# MCU_CTRL_MMR_MCU_CTRL_MMR_CFG0_04500000h register map
Vendor: Texas Instruments
Registers are 32-bit, read-write, reset 0x0 unless marked. A register's access mark holds for its fields unless they carry their own. Offsets are as the file gives them; [hi:lo] are bit positions; {n}, {i} and the like mark numbered series.

## MCU_CTRL_MMR_CFG0 (part 3 of 3)
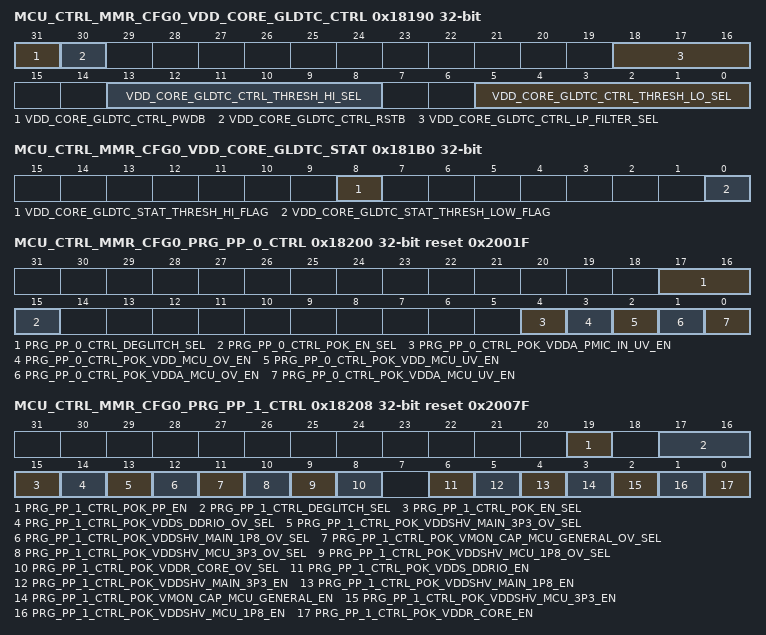
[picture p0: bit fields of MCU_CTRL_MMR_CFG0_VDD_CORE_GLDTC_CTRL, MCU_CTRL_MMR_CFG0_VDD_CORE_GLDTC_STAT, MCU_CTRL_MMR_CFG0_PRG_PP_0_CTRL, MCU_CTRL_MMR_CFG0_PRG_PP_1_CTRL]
0x18190 MCU_CTRL_MMR_CFG0_VDD_CORE_GLDTC_CTRL
  [31] VDD_CORE_GLDTC_CTRL_PWDB — Power down - active low. 0 - Deactivate all functions 1 - Activate glitch detectors Reset Source: mcu_chip1_rst_n
  [30] VDD_CORE_GLDTC_CTRL_RSTB — Reset - active low. To ensure proper operation, rstb must be not be de-asserted for at least 100 ns after power-up (pwdb de-asserted). Additionally, rstb must be toggled low at least 200 ns after any change in threshold or low-pass filter settings to prevent abnormal trigger events. 0 - Reset glitch detector flags 1 - Glitch detection flags are activated Reset Source: mcu_chip1_rst_n
  [18:16] VDD_CORE_GLDTC_CTRL_LP_FILTER_SEL — Selects the glitch detect low-pass filter bandwidthField values (others are reserved):3'b000 - 150 kHz3'b001 - 125 kHz3'b010 - 100 kHz3'b011 - 80 kHz3'b100 - 60 kHz3'b101 - 45 kHz3'b110 - 30 kHz3'b111 - 15 kHz Reset Source: mcu_chip1_rst_n
  [13:8] VDD_CORE_GLDTC_CTRL_THRESH_HI_SEL — Selects the high voltage glitch threshold as a percentage of the monitored voltageField values (others are reserved):6'b000000 - 93.5% of VDD6'b000001 - 94.0% of VDD6'b000010 - 94.5% of VDD6'b000011 - 95.0% of VDD6'b000100 - 95.5% of VDD6'b000101 - 96.0% of VDD6'b000110 - 96.5% of VDD6'b000111 - 97.0% of VDD6'b001000 - 97.5% of VDD6'b001001 - 98.0% of VDD6'b001010 - 98.5% of VDD6'b001011 - 99.0% of VDD6'b001100 - 99.5% of VDD6'b001101 - 100.0% of VDD6'b001110 - 100.5% of VDD6'b001111 - 101.0% of VDD6'b010000 - 101.5% of VDD6'b010001 - 102.0% of VDD6'b010010 - 102.5% of VDD6'b010011 - 103.0% of VDD6'b010100 - 103.5% of VDD6'b010101 - 104.0% of VDD6'b010110 - 104.5% of VDD6'b010111 - 105.0% of VDD6'b011000 - 105.5% of VDD6'b011001 - 106.0% of VDD6'b011010 - 106.5% of VDD6'b011011 - 107.0% of VDD6'b011100 - 107.5% of VDD6'b011101 - 108.0% of VDD6'b011110 - 108.5% of VDD6'b011111 - 109.0% of VDD6'b100000 - 109.5% of VDD6'b100001 - 110.0% of VDD6'b100010 - 111.0% of VDD6'b100011 - 112.0% of VDD6'b100100 - 113.0% of VDD6'b100101 - 114.0% of VDD6'b100110 - 115.0% of VDD6'b100111 - 116.0% of VDD6'b101000 - 117.0% of VDD6'b101001 - 118.0% of VDD6'b101010 - 119.0% of VDD6'b101011 - 120.0% of VDD6'b101100 - 121.0% of VDD6'b101101 - 122.0% of VDD6'b101110 - 123.0% of VDD6'b101111 - 124.0% of VDD6'b110000 - 125.0% of VDD6'b110001 - 126.0% of VDD6'b110010 - 127.0% of VDD6'b110011 - 128.0% of VDD6'b110100 - 129.0% of VDD6'b110101 - 130.0% of VDD6'b110110 - 131.0% of VDD6'b110111 - 132.0% of VDD6'b111000 - 133.0% of VDD6'b111001 - 134.0% of VDD6'b111010 - 135.0% of VDD6'b111011 - 136.0% of VDD6'b111100 - 137.0% of VDD6'b111101 - 138.0% of VDD6'b111110 - 139.0% of VDD6'b111111 - 140.0% of VDD Reset Source: mcu_chip1_rst_n
  [5:0] VDD_CORE_GLDTC_CTRL_THRESH_LO_SEL — Selects the low voltage glitch threshold as a percentage of the monitored voltageField values (others are reserved):6'b000000 - 106.5% of VDD6'b000001 - 106.0% of VDD6'b000010 - 105.5% of VDD6'b000011 - 105.0% of VDD6'b000100 - 104.5% of VDD6'b000101 - 104.0% of VDD6'b000110 - 103.5% of VDD6'b000111 - 103.0% of VDD6'b001000 - 102.5% of VDD6'b001001 - 102.0% of VDD6'b001010 - 101.5% of VDD6'b001011 - 101.0% of VDD6'b001100 - 100.5% of VDD6'b001101 - 100.0% of VDD6'b001110 - 99.5% of VDD6'b001111 - 99.0% of VDD6'b010000 - 98.5% of VDD6'b010001 - 98.0% of VDD6'b010010 - 97.5% of VDD6'b010011 - 97.0% of VDD6'b010100 - 96.5% of VDD6'b010101 - 96.0% of VDD6'b010110 - 95.5% of VDD6'b010111 - 95.0% of VDD6'b011000 - 94.5% of VDD6'b011001 - 94.0% of VDD6'b011010 - 93.5% of VDD6'b011011 - 93.0% of VDD6'b011100 - 92.5% of VDD6'b011101 - 92.0% of VDD6'b011110 - 91.5% of VDD6'b011111 - 91.0% of VDD6'b100000 - 90.5% of VDD6'b100001 - 90.0% of VDD6'b100010 - 89.0% of VDD6'b100011 - 88.0% of VDD6'b100100 - 87.0% of VDD6'b100101 - 86.0% of VDD6'b100110 - 85.0% of VDD6'b100111 - 84.0% of VDD6'b101000 - 83.0% of VDD6'b101001 - 82.0% of VDD6'b101010 - 81.0% of VDD6'b101011 - 80.0% of VDD6'b101100 - 79.0% of VDD6'b101101 - 78.0% of VDD6'b101110 - 77.0% of VDD6'b101111 - 76.0% of VDD6'b110000 - 75.0% of VDD6'b110001 - 74.0% of VDD6'b110010 - 73.0% of VDD6'b110011 - 72.0% of VDD6'b110100 - 71.0% of VDD6'b110101 - 70.0% of VDD6'b110110 - 69.0% of VDD6'b110111 - 68.0% of VDD6'b111000 - 67.0% of VDD6'b111001 - 66.0% of VDD6'b111010 - 65.0% of VDD6'b111011 - 64.0% of VDD6'b111100 - 63.0% of VDD6'b111101 - 62.0% of VDD6'b111110 - 61.0% of VDD6'b111111 - 60.0% of VDD Reset Source: mcu_chip1_rst_n
0x181B0 MCU_CTRL_MMR_CFG0_VDD_CORE_GLDTC_STAT ro
  [8] VDD_CORE_GLDTC_STAT_THRESH_HI_FLAG — High voltage flag. This flag is cleared by clearing the VDD_CORE_GLDTC_CTRL_rstb bit. 0 - No high voltage detected 1 - Voltage above the high voltage threshold was detected. Reset Source: mcu_chip1_rst_n
  [0] VDD_CORE_GLDTC_STAT_THRESH_LOW_FLAG — Low voltage flag. This flag is cleared by clearing the VDD_CORE_GLDTC_CTRL_rstb bit. 0 - No low voltage detected 1 - Voltage below the low voltage threshold was detected. Reset Source: mcu_chip1_rst_n
0x18200 MCU_CTRL_MMR_CFG0_PRG_PP_0_CTRL reset 0x2001F
  [17:16] PRG_PP_0_CTRL_DEGLITCH_SEL — Deglitch period for PRG_PP0 POKs:2'b00 - 5 us2'b01 -10 us2'b10 - 15 us2'b11 - 20us Reset Source: mod_por_rst_n
  [15] PRG_PP_0_CTRL_POK_EN_SEL — Select POK activate source0 - POK activates come from hardware tie-offs1 - POK activates come from PRG_PP0_CTRL register Reset Source: mod_por_rst_n
  [4] PRG_PP_0_CTRL_POK_VDDA_PMIC_IN_UV_EN — Activate VDDA_PMIC_IN undervoltage POK detection0 - POK detection deactivated1 - POK detection activated Reset Source: mod_por_rst_n
  [3] PRG_PP_0_CTRL_POK_VDD_MCU_OV_EN — Activate VDD_MCU overvoltage POK detection0 - POK detection deactivated1 - POK detection activated Reset Source: mod_por_rst_n
  [2] PRG_PP_0_CTRL_POK_VDD_MCU_UV_EN — Activate VDD_MCU undervoltage POK detection0 - POK detection deactivated1 - POK detection activated Reset Source: mod_por_rst_n
  [1] PRG_PP_0_CTRL_POK_VDDA_MCU_OV_EN — Activate 1.8V VDDA_MCU overvoltage POK detection0 - POK detection deactivated1 - POK detection activated Reset Source: mod_por_rst_n
  [0] PRG_PP_0_CTRL_POK_VDDA_MCU_UV_EN — Activate 1.8V VDDA_MCU undervoltage POK detection0 - POK detection deactivated1 - POK detection activated Reset Source: mod_por_rst_n
0x18208 MCU_CTRL_MMR_CFG0_PRG_PP_1_CTRL reset 0x2007F
  [19] PRG_PP_1_CTRL_POK_PP_EN — POK ping-pong activate. When set, activatesautomatic switching between undervoltage andovervoltage detection on PRG_PP1 (POK_VDDR_CORE, POK_VDDSHV_MCU_1P8, POK_VDDSHV_MCU_3P3, POK_VMON_CAP_MCU_GENERAL, POK_VDDSHV_MAIN_1P8, POK_VDDSHV_MAIN_3P3, and POK_VDDS_DDRIO) POKs. This bit has no effect if the POK's ov_sel bit = 1.0 - No pingpong operation. UV/OV operationselected by each POK ov_sel bit1 - Pingpong operation activated . Reset Source: mod_por_rst_n
  [17:16] PRG_PP_1_CTRL_DEGLITCH_SEL — Deglitch period for PRG_PP1 POKs:2'b00 - 5 us2'b01 -10 us2'b10 - 15 us2'b11 - 20us Reset Source: mod_por_rst_n
  [15] PRG_PP_1_CTRL_POK_EN_SEL — Select POK activate source0 - POK activates come from hardware tie-offs1 - POK activates come from PRG_PP1_CTRL register Reset Source: mod_por_rst_n
  [14] PRG_PP_1_CTRL_POK_VDDS_DDRIO_OV_SEL — POK_VDDS_DDRIO mode: 0 = Undervoltage (pok_pp_en = 0) Ping-Pong (pok_pp_en = 1) 1 = Overvoltage (pok_pp_en = x) Reset Source: mod_por_rst_n
  [13] PRG_PP_1_CTRL_POK_VDDSHV_MAIN_3P3_OV_SEL — POK_VDDSHV_MAIN_3P3 mode: 0 = Undervoltage (pok_pp_en = 0) Ping-Pong (pok_pp_en = 1) 1 = Overvoltage (pok_pp_en = x) Reset Source: mod_por_rst_n
  [12] PRG_PP_1_CTRL_POK_VDDSHV_MAIN_1P8_OV_SEL — POK_VDDSHV_MAIN_1P8 mode: 0 = Undervoltage (pok_pp_en = 0) Ping-Pong (pok_pp_en = 1) 1 = Overvoltage (pok_pp_en = x) Reset Source: mod_por_rst_n
  [11] PRG_PP_1_CTRL_POK_VMON_CAP_MCU_GENERAL_OV_SEL — POK_VMON_CAP_MCU_GENERAL mode: 0 = Undervoltage (pok_pp_en = 0) Ping-Pong (pok_pp_en = 1) 1 = Overvoltage (pok_pp_en = x) Reset Source: mod_por_rst_n
  [10] PRG_PP_1_CTRL_POK_VDDSHV_MCU_3P3_OV_SEL — POK_VDDSHV_MCU_3P3 mode: 0 = Undervoltage (pok_pp_en = 0) Ping-Pong (pok_pp_en = 1) 1 = Overvoltage (pok_pp_en = x) Reset Source: mod_por_rst_n
  [9] PRG_PP_1_CTRL_POK_VDDSHV_MCU_1P8_OV_SEL — POK_VDDSHV_MCU_1P8 mode: 0 = Undervoltage (pok_pp_en = 0) Ping-Pong (pok_pp_en = 1) 1 = Overvoltage (pok_pp_en = x) Reset Source: mod_por_rst_n
  [8] PRG_PP_1_CTRL_POK_VDDR_CORE_OV_SEL — POK_VDDR_CORE Mode: 0 = Undervoltage (pok_pp_en = 0) Ping-Pong (pok_pp_en = 1) 1 = Overvoltage (pok_pp_en = x) Reset Source: mod_por_rst_n
  [6] PRG_PP_1_CTRL_POK_VDDS_DDRIO_EN — Activate POK_VDDS_DDRIO (if pok_en_sel = 1): 0 = POK Detection Deactivated 1 = POK Detection Activated Reset Source: mod_por_rst_n
  [5] PRG_PP_1_CTRL_POK_VDDSHV_MAIN_3P3_EN — Activate POK_VDDSHV_MAIN_3P3 (if pok_en_sel = 1): 0 = POK Detection Deactivated 1 = POK Detection Activated Reset Source: mod_por_rst_n
  [4] PRG_PP_1_CTRL_POK_VDDSHV_MAIN_1P8_EN — Activate POK_VDDSHV_MAIN_1P8 (if pok_en_sel = 1): 0 = POK Detection Deactivated 1 = POK Detection Activated Reset Source: mod_por_rst_n
  [3] PRG_PP_1_CTRL_POK_VMON_CAP_MCU_GENERAL_EN — Activate POK_VMON_CAP_MCU_GENERAL (if pok_en_sel = 1): 0 = POK Detection Deactivated 1 = POK Detection Activated Reset Source: mod_por_rst_n
  [2] PRG_PP_1_CTRL_POK_VDDSHV_MCU_3P3_EN — Activate POK_VDDSHV_MCU_3P3 (if pok_en_sel = 1): 0 = POK Detection Deactivated 1 = POK Detection Activated Reset Source: mod_por_rst_n
  [1] PRG_PP_1_CTRL_POK_VDDSHV_MCU_1P8_EN — Activate POK_VDDSHV_MCU_1P8 (if pok_en_sel = 1): 0 = POK Detection Deactivated 1 = POK Detection Activated Reset Source: mod_por_rst_n
  [0] PRG_PP_1_CTRL_POK_VDDR_CORE_EN — Activate POK_VDDR_CORE (if pok_en_sel = 1): 0 = POK Detection Deactivated 1 = POK Detection Activated Reset Source: mod_por_rst_n
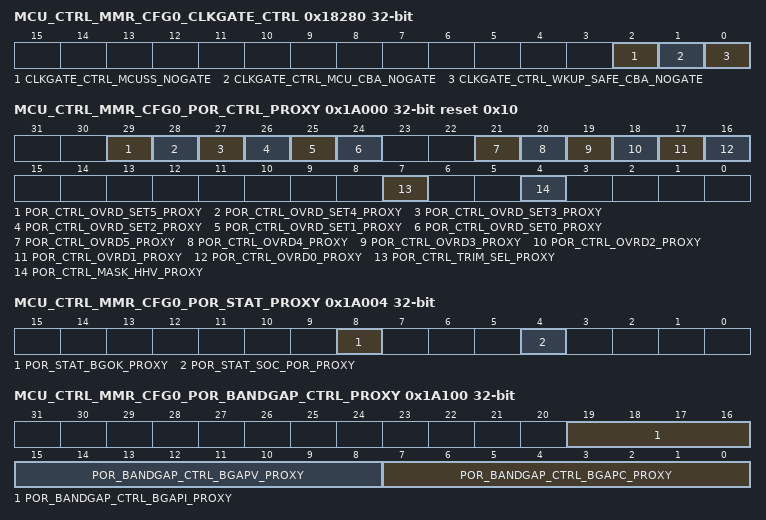
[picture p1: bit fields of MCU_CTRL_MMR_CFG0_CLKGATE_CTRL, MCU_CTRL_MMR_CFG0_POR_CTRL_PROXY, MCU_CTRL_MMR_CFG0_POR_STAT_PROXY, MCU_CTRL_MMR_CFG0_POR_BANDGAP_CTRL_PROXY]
0x18280 MCU_CTRL_MMR_CFG0_CLKGATE_CTRL
  [2] CLKGATE_CTRL_MCUSS_NOGATE — MCU Subsystem clock gate deactivate. 0 - Clocks are gated on idle for power savings 1 - Clocks are not gated on idle, power saving deactivated Reset Source: mod_por_rst_n
  [1] CLKGATE_CTRL_MCU_CBA_NOGATE — MCU domain Data bus (mcu_cbass) clock gate deactivate. 0 - Clocks are gated on idle for power savings 1 - Clocks are not gated on idle, power saving deactivated Reset Source: mod_por_rst_n
  [0] CLKGATE_CTRL_WKUP_SAFE_CBA_NOGATE — WKUP domain Infrastructure bus (wkup_safe_cbass) clock gate deactivate. 0 - Clocks are gated on idle for power savings 1 - Clocks are not gated on idle, power saving deactivated Reset Source: mod_por_rst_n
0x19008 MCU_CTRL_MMR_CFG0_LOCK6_KICK0
  [31:0] LOCK6_KICK0 — - KICK0 component Reset Source: mod_g_rst_n
0x1900C MCU_CTRL_MMR_CFG0_LOCK6_KICK1
  [31:0] LOCK6_KICK1 — - KICK1 component Reset Source: mod_g_rst_n
{0x19100+4i} MCU_CTRL_MMR_CFG0_CLAIMREG_P6_R{i}_READONLY ro (i=0..5)
  [31:0] CLAIMREG_P6_R{i}_READONLY — Claim bits for Partition 6 Reset Source: mod_g_rst_n
0x1A000 MCU_CTRL_MMR_CFG0_POR_CTRL_PROXY reset 0x10
  [29] POR_CTRL_OVRD_SET5_PROXY — Reserved override set Reset Source: mod_por_rst_n
  [28] POR_CTRL_OVRD_SET4_PROXY — POKLVB override set Reset Source: mod_por_rst_n
  [27] POR_CTRL_OVRD_SET3_PROXY — POKLVA override set Reset Source: mod_por_rst_n
  [26] POR_CTRL_OVRD_SET2_PROXY — POKHV override set Reset Source: mod_por_rst_n
  [25] POR_CTRL_OVRD_SET1_PROXY — BGOK override set Reset Source: mod_por_rst_n
  [24] POR_CTRL_OVRD_SET0_PROXY — PORHV override set Reset Source: mod_por_rst_n
  [21] POR_CTRL_OVRD5_PROXY — Reserved override activate Reset Source: mod_por_rst_n
  [20] POR_CTRL_OVRD4_PROXY — POKLVB override activate Reset Source: mod_por_rst_n
  [19] POR_CTRL_OVRD3_PROXY — POKLVA override activate Reset Source: mod_por_rst_n
  [18] POR_CTRL_OVRD2_PROXY — POKHV override activate Reset Source: mod_por_rst_n
  [17] POR_CTRL_OVRD1_PROXY — BGOK override activate Reset Source: mod_por_rst_n
  [16] POR_CTRL_OVRD0_PROXY — PORHV override activate Reset Source: mod_por_rst_n
  [7] POR_CTRL_TRIM_SEL_PROXY — POR Trim Select 0 - Trim selections for Bandgap and POKs come from HHV defaults 1 - Trim selections for Bandgap and POKs come from POR_BANDGAP_CTRL and POR_POKxxx_CTRL registers Reset Source: mod_por_rst_n
  [4] POR_CTRL_MASK_HHV_PROXY — Mask HHV/SOC_PORz outputs when applying new trim values Reset Source: mod_por_rst_n
0x1A004 MCU_CTRL_MMR_CFG0_POR_STAT_PROXY ro
  [8] POR_STAT_BGOK_PROXY — Bandgap OK status Reset Source: mod_por_rst_n
  [4] POR_STAT_SOC_POR_PROXY — POR module status 0 - Module is in functional mode 1 - Module is in reset mode Reset Source: mod_por_rst_n
0x1A100 MCU_CTRL_MMR_CFG0_POR_BANDGAP_CTRL_PROXY
  [19:16] POR_BANDGAP_CTRL_BGAPI_PROXY — Bandgap output current trim bits Reset Source: mod_por_rst_n
  [15:8] POR_BANDGAP_CTRL_BGAPV_PROXY — Bandgap output voltage magnitude trim bits Reset Source: mod_por_rst_n
  [7:0] POR_BANDGAP_CTRL_BGAPC_PROXY — Bandgap slope trim bits. Bit7 is used to calculate the offset Reset Source: mod_por_rst_n
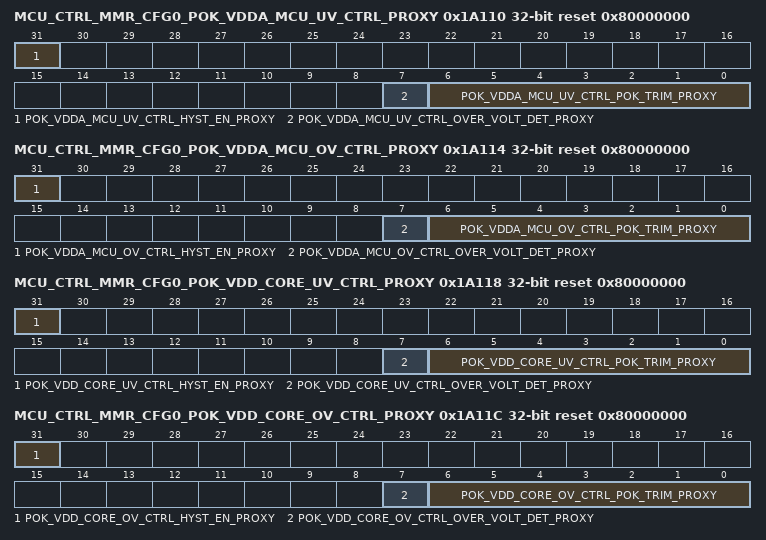
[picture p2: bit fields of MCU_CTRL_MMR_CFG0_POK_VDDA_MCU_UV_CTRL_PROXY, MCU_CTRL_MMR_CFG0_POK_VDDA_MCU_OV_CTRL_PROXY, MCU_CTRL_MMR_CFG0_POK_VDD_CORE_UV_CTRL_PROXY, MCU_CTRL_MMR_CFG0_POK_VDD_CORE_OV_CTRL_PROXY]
0x1A110 MCU_CTRL_MMR_CFG0_POK_VDDA_MCU_UV_CTRL_PROXY reset 0x80000000
  [31] POK_VDDA_MCU_UV_CTRL_HYST_EN_PROXY — Activate POK hysteresis Reset Source: mod_por_rst_n
  [7] POK_VDDA_MCU_UV_CTRL_OVER_VOLT_DET_PROXY — Over / under voltage detection mode 0 - Under voltage detection 1 - Over voltage detection Reset Source: mod_por_rst_n
  [6:0] POK_VDDA_MCU_UV_CTRL_POK_TRIM_PROXY — POK Trim Bits Reset Source: mod_por_rst_n
0x1A114 MCU_CTRL_MMR_CFG0_POK_VDDA_MCU_OV_CTRL_PROXY reset 0x80000000
  [31] POK_VDDA_MCU_OV_CTRL_HYST_EN_PROXY — Activate POK hysteresis Reset Source: mod_por_rst_n
  [7] POK_VDDA_MCU_OV_CTRL_OVER_VOLT_DET_PROXY — Over / under voltage detection mode 0 - Under voltage detection 1 - Over voltage detection Reset Source: mod_por_rst_n
  [6:0] POK_VDDA_MCU_OV_CTRL_POK_TRIM_PROXY — POK Trim Bits Reset Source: mod_por_rst_n
0x1A118 MCU_CTRL_MMR_CFG0_POK_VDD_CORE_UV_CTRL_PROXY reset 0x80000000
  [31] POK_VDD_CORE_UV_CTRL_HYST_EN_PROXY — Activate POK hysteresis Reset Source: mod_por_rst_n
  [7] POK_VDD_CORE_UV_CTRL_OVER_VOLT_DET_PROXY — Over / under voltage detection mode 0 - Under voltage detection 1 - Over voltage detection Reset Source: mod_por_rst_n
  [6:0] POK_VDD_CORE_UV_CTRL_POK_TRIM_PROXY — POK Trim Bits Reset Source: mod_por_rst_n
0x1A11C MCU_CTRL_MMR_CFG0_POK_VDD_CORE_OV_CTRL_PROXY reset 0x80000000
  [31] POK_VDD_CORE_OV_CTRL_HYST_EN_PROXY — Activate POK hysteresis Reset Source: mod_por_rst_n
  [7] POK_VDD_CORE_OV_CTRL_OVER_VOLT_DET_PROXY — Over / under voltage detection mode 0 - Under voltage detection 1 - Over voltage detection Reset Source: mod_por_rst_n
  [6:0] POK_VDD_CORE_OV_CTRL_POK_TRIM_PROXY — POK Trim Bits Reset Source: mod_por_rst_n
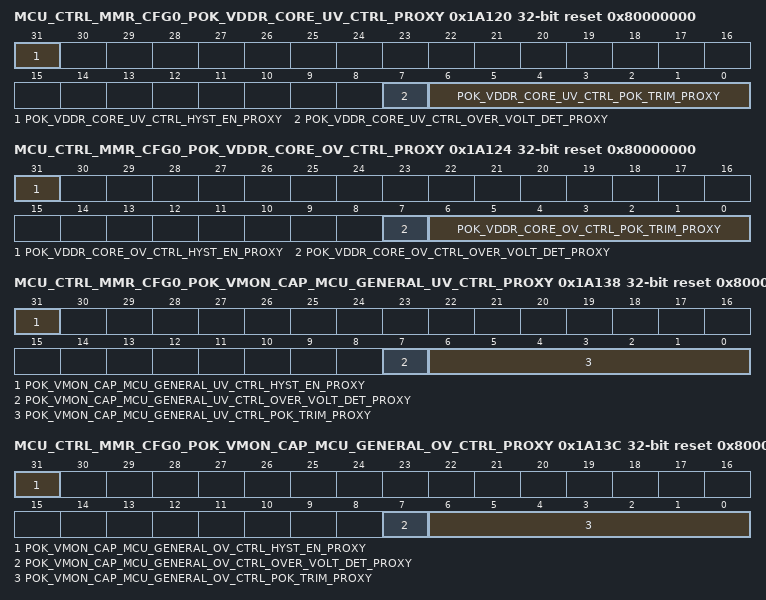
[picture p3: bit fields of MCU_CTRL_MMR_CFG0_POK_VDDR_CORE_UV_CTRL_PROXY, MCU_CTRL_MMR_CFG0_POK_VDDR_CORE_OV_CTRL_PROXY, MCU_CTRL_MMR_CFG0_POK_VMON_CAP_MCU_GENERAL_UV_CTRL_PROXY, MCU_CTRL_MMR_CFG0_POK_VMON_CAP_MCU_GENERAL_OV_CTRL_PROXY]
0x1A120 MCU_CTRL_MMR_CFG0_POK_VDDR_CORE_UV_CTRL_PROXY reset 0x80000000
  [31] POK_VDDR_CORE_UV_CTRL_HYST_EN_PROXY — Activate POK hysteresis Reset Source: mod_por_rst_n
  [7] POK_VDDR_CORE_UV_CTRL_OVER_VOLT_DET_PROXY — Over / under voltage detection mode 0 - Under voltage detection 1 - Over voltage detection Reset Source: mod_por_rst_n
  [6:0] POK_VDDR_CORE_UV_CTRL_POK_TRIM_PROXY — POK Trim Bits Reset Source: mod_por_rst_n
0x1A124 MCU_CTRL_MMR_CFG0_POK_VDDR_CORE_OV_CTRL_PROXY reset 0x80000000
  [31] POK_VDDR_CORE_OV_CTRL_HYST_EN_PROXY — Activate POK hysteresis Reset Source: mod_por_rst_n
  [7] POK_VDDR_CORE_OV_CTRL_OVER_VOLT_DET_PROXY — Over / under voltage detection mode 0 - Under voltage detection 1 - Over voltage detection Reset Source: mod_por_rst_n
  [6:0] POK_VDDR_CORE_OV_CTRL_POK_TRIM_PROXY — POK Trim Bits Reset Source: mod_por_rst_n
0x1A138 MCU_CTRL_MMR_CFG0_POK_VMON_CAP_MCU_GENERAL_UV_CTRL_PROXY reset 0x80000000
  [31] POK_VMON_CAP_MCU_GENERAL_UV_CTRL_HYST_EN_PROXY — Activate POK hysteresis Reset Source: mod_por_rst_n
  [7] POK_VMON_CAP_MCU_GENERAL_UV_CTRL_OVER_VOLT_DET_PROXY — Over / under voltage detection mode 0 - Under voltage detection 1 - Over voltage detection Reset Source: mod_por_rst_n
  [6:0] POK_VMON_CAP_MCU_GENERAL_UV_CTRL_POK_TRIM_PROXY — POK Trim Bits Reset Source: mod_por_rst_n
0x1A13C MCU_CTRL_MMR_CFG0_POK_VMON_CAP_MCU_GENERAL_OV_CTRL_PROXY reset 0x80000000
  [31] POK_VMON_CAP_MCU_GENERAL_OV_CTRL_HYST_EN_PROXY — Activate POK hysteresis Reset Source: mod_por_rst_n
  [7] POK_VMON_CAP_MCU_GENERAL_OV_CTRL_OVER_VOLT_DET_PROXY — Over / under voltage detection mode 0 - Under voltage detection 1 - Over voltage detection Reset Source: mod_por_rst_n
  [6:0] POK_VMON_CAP_MCU_GENERAL_OV_CTRL_POK_TRIM_PROXY — POK Trim Bits Reset Source: mod_por_rst_n
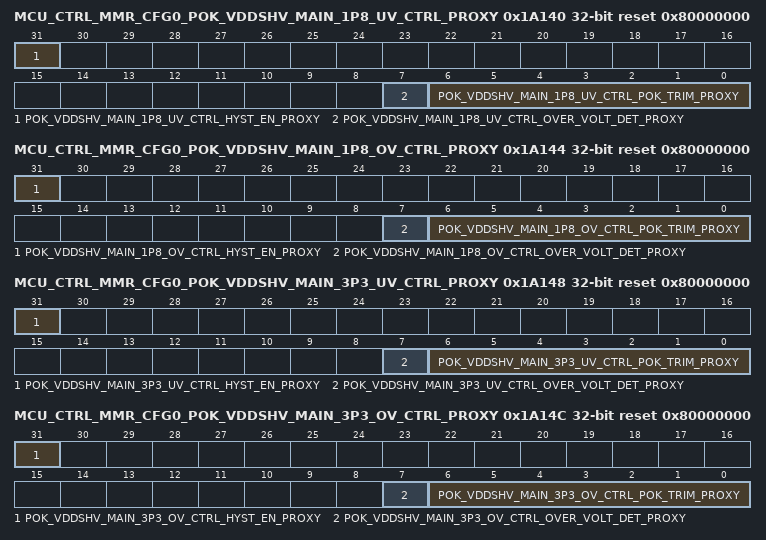
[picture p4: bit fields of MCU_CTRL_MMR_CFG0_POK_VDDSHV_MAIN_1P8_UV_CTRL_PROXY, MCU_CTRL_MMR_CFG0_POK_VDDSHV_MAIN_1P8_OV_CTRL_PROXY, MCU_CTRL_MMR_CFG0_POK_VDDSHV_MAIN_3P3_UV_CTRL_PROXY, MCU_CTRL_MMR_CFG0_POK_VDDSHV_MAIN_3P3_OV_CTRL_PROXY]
0x1A140 MCU_CTRL_MMR_CFG0_POK_VDDSHV_MAIN_1P8_UV_CTRL_PROXY reset 0x80000000
  [31] POK_VDDSHV_MAIN_1P8_UV_CTRL_HYST_EN_PROXY — Activate POK hysteresis Reset Source: mod_por_rst_n
  [7] POK_VDDSHV_MAIN_1P8_UV_CTRL_OVER_VOLT_DET_PROXY — Over / under voltage detection mode 0 - Under voltage detection 1 - Over voltage detection Reset Source: mod_por_rst_n
  [6:0] POK_VDDSHV_MAIN_1P8_UV_CTRL_POK_TRIM_PROXY — POK Trim Bits Reset Source: mod_por_rst_n
0x1A144 MCU_CTRL_MMR_CFG0_POK_VDDSHV_MAIN_1P8_OV_CTRL_PROXY reset 0x80000000
  [31] POK_VDDSHV_MAIN_1P8_OV_CTRL_HYST_EN_PROXY — Activate POK hysteresis Reset Source: mod_por_rst_n
  [7] POK_VDDSHV_MAIN_1P8_OV_CTRL_OVER_VOLT_DET_PROXY — Over / under voltage detection mode 0 - Under voltage detection 1 - Over voltage detection Reset Source: mod_por_rst_n
  [6:0] POK_VDDSHV_MAIN_1P8_OV_CTRL_POK_TRIM_PROXY — POK Trim Bits Reset Source: mod_por_rst_n
0x1A148 MCU_CTRL_MMR_CFG0_POK_VDDSHV_MAIN_3P3_UV_CTRL_PROXY reset 0x80000000
  [31] POK_VDDSHV_MAIN_3P3_UV_CTRL_HYST_EN_PROXY — Activate POK hysteresis Reset Source: mod_por_rst_n
  [7] POK_VDDSHV_MAIN_3P3_UV_CTRL_OVER_VOLT_DET_PROXY — Over / under voltage detection mode 0 - Under voltage detection 1 - Over voltage detection Reset Source: mod_por_rst_n
  [6:0] POK_VDDSHV_MAIN_3P3_UV_CTRL_POK_TRIM_PROXY — POK Trim Bits Reset Source: mod_por_rst_n
0x1A14C MCU_CTRL_MMR_CFG0_POK_VDDSHV_MAIN_3P3_OV_CTRL_PROXY reset 0x80000000
  [31] POK_VDDSHV_MAIN_3P3_OV_CTRL_HYST_EN_PROXY — Activate POK hysteresis Reset Source: mod_por_rst_n
  [7] POK_VDDSHV_MAIN_3P3_OV_CTRL_OVER_VOLT_DET_PROXY — Over / under voltage detection mode 0 - Under voltage detection 1 - Over voltage detection Reset Source: mod_por_rst_n
  [6:0] POK_VDDSHV_MAIN_3P3_OV_CTRL_POK_TRIM_PROXY — POK Trim Bits Reset Source: mod_por_rst_n
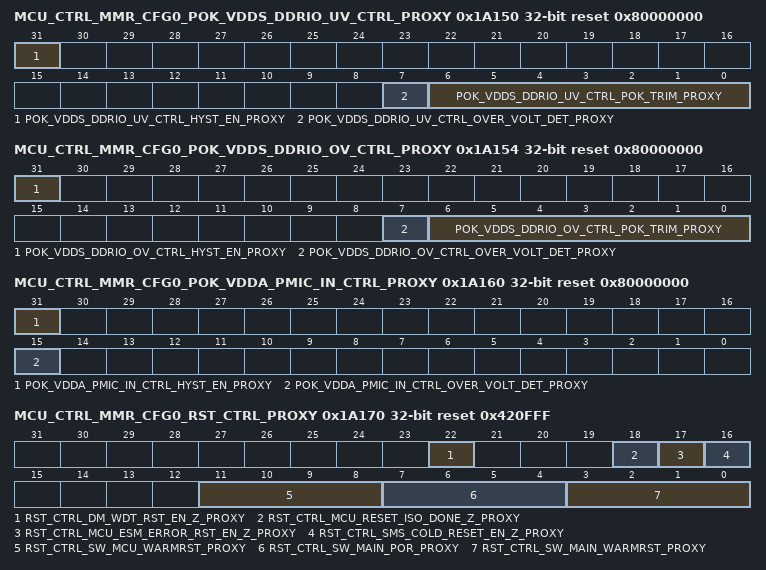
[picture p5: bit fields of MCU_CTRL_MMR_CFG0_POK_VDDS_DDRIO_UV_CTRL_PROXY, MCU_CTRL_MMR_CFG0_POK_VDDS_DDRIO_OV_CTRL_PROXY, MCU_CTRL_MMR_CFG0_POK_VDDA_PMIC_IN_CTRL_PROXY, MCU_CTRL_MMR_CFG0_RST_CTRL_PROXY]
0x1A150 MCU_CTRL_MMR_CFG0_POK_VDDS_DDRIO_UV_CTRL_PROXY reset 0x80000000
  [31] POK_VDDS_DDRIO_UV_CTRL_HYST_EN_PROXY — Activate POK hysteresis Reset Source: mod_por_rst_n
  [7] POK_VDDS_DDRIO_UV_CTRL_OVER_VOLT_DET_PROXY — Over / under voltage detection mode 0 - Under voltage detection 1 - Over voltage detection Reset Source: mod_por_rst_n
  [6:0] POK_VDDS_DDRIO_UV_CTRL_POK_TRIM_PROXY — POK Trim Bits Reset Source: mod_por_rst_n
0x1A154 MCU_CTRL_MMR_CFG0_POK_VDDS_DDRIO_OV_CTRL_PROXY reset 0x80000000
  [31] POK_VDDS_DDRIO_OV_CTRL_HYST_EN_PROXY — Activate POK hysteresis Reset Source: mod_por_rst_n
  [7] POK_VDDS_DDRIO_OV_CTRL_OVER_VOLT_DET_PROXY — Over / under voltage detection mode 0 - Under voltage detection 1 - Over voltage detection Reset Source: mod_por_rst_n
  [6:0] POK_VDDS_DDRIO_OV_CTRL_POK_TRIM_PROXY — POK Trim Bits Reset Source: mod_por_rst_n
0x1A160 MCU_CTRL_MMR_CFG0_POK_VDDA_PMIC_IN_CTRL_PROXY reset 0x80000000
  [31] POK_VDDA_PMIC_IN_CTRL_HYST_EN_PROXY — Activate POK hysteresis Reset Source: mod_por_rst_n
  [15] POK_VDDA_PMIC_IN_CTRL_OVER_VOLT_DET_PROXY — Over / under voltage detection mode 0 - Under voltage detection 1 - Over voltage detection Reset Source: mod_por_rst_n
0x1A170 MCU_CTRL_MMR_CFG0_RST_CTRL_PROXY reset 0x420FFF
  [22] RST_CTRL_DM_WDT_RST_EN_Z_PROXY — Deactivate Reset from DM WDT propogating to MCU domain: 0 - Activated 1 - Deactivated Reset Source: mcu_chip1_rst_n
  [18] RST_CTRL_MCU_RESET_ISO_DONE_Z_PROXY — MCU can set this bit to block warm reset in the main domain which is useful when the MCU may be accessing main domain resources (peripherals, memory..). In this case, the MCU will be notified via an interrupt that there is an outstanding warm reset request for the main domain. Once notified, MCU needs to finish any outstanding operations in has with main domain resources and then clear this bit. After this bit is cleared, the main domain warm reset will unblocked and the warm reset sequence may continue. 0 - Reset of Main Domain is not Blocked by MCU Domain 1 - Reset of Main Domain is Blocked by MCU Domain Reset Source: mcu_chip1_rst_n
  [17] RST_CTRL_MCU_ESM_ERROR_RST_EN_Z_PROXY — Deactivate Reset of MCU by ESM 0 - Activated 1 - Deactivated Reset Source: mcu_chip1_rst_n
  [16] RST_CTRL_SMS_COLD_RESET_EN_Z_PROXY — Deactivate Reset of MCU by SMS 0 - Activated 1 - Deactivated Reset Source: mcu_chip1_rst_n
  [11:8] RST_CTRL_SW_MCU_WARMRST_PROXY — This is a fault tolerant bitfield. Causes MCU Domain Warm Reset when set to 4'b0110, Bits will reset to 4'b1111 Reset Source: mcu_chip1_rst_n
  [7:4] RST_CTRL_SW_MAIN_POR_PROXY — This is a fault tolerant bitfield. Causes MAIN Domain Power On Reset when set to 4'b0110, Bits will reset to 4'b1111 Reset Source: main_chip1_rst_n
  [3:0] RST_CTRL_SW_MAIN_WARMRST_PROXY — This is a fault tolerant bitfield. Causes MAIN Domain Warm Reset when set to 4'b0110, Bits will reset to 4'b1111 Reset Source: main_chip1_rst_n
0x1A174 MCU_CTRL_MMR_CFG0_RST_STAT_PROXY ro
  [0] RST_STAT_MAIN_RESETSTATZ_PROXY — Status of Main Domain Reset: 0 = Reset Asserted 1 = Reset Deasserted Reset Source: mcu_chip1_rst_n
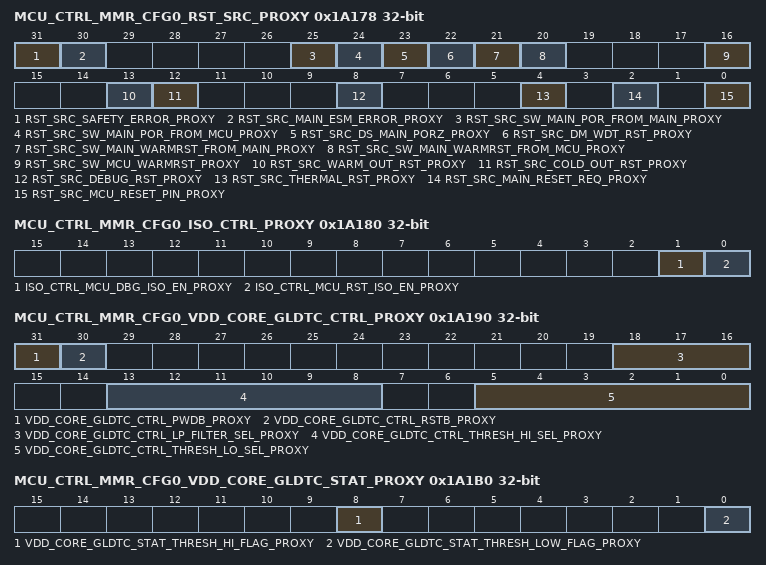
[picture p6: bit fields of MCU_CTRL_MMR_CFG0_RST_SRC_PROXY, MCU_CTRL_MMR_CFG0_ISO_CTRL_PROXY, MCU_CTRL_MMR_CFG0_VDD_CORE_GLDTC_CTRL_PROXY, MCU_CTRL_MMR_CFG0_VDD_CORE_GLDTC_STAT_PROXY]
0x1A178 MCU_CTRL_MMR_CFG0_RST_SRC_PROXY access not given
  [31] RST_SRC_SAFETY_ERROR_PROXY — Reset Caused by MCU ESM Error Reset Source: mod_por_rst_n (access R/W1TC)
  [30] RST_SRC_MAIN_ESM_ERROR_PROXY — Reset Caused by Main ESM Error Reset Source: mod_por_rst_n (access R/W1TC)
  [25] RST_SRC_SW_MAIN_POR_FROM_MAIN_PROXY — Software Main Power On Reset From MAIN CTRL MMR Reset Source: mod_por_rst_n (access R/W1TC)
  [24] RST_SRC_SW_MAIN_POR_FROM_MCU_PROXY — Software Main Power On Reset From MCU CTRL MMR Reset Source: mod_por_rst_n (access R/W1TC)
  [23] RST_SRC_DS_MAIN_PORZ_PROXY — Reset of Main/Wkup Domains while in Deep Sleep, as a result of an MCU Warm Reset Reset Source: mod_por_rst_n (access R/W1TC)
  [22] RST_SRC_DM_WDT_RST_PROXY — Watchdog Initiated Reset Reset Source: mod_por_rst_n (access R/W1TC)
  [21] RST_SRC_SW_MAIN_WARMRST_FROM_MAIN_PROXY — Software Main Warm Reset from MAIN CTRL MMR Reset Source: mod_por_rst_n (access R/W1TC)
  [20] RST_SRC_SW_MAIN_WARMRST_FROM_MCU_PROXY — Software Main Warm Reset From MCU CTRL MMR Reset Source: mod_por_rst_n (access R/W1TC)
  [16] RST_SRC_SW_MCU_WARMRST_PROXY — Software Warm Reset Reset Source: mod_por_rst_n (access R/W1TC)
  [13] RST_SRC_WARM_OUT_RST_PROXY — SMS Warm Reset Reset Source: mod_por_rst_n (access R/W1TC)
  [12] RST_SRC_COLD_OUT_RST_PROXY — SMS Cold Reset Reset Source: mod_por_rst_n (access R/W1TC)
  [8] RST_SRC_DEBUG_RST_PROXY — Debug Subsystem Initiated Reset Reset Source: mod_por_rst_n (access R/W1TC)
  [4] RST_SRC_THERMAL_RST_PROXY — Thermal Reset Reset Source: mod_por_rst_n (access R/W1TC)
  [2] RST_SRC_MAIN_RESET_REQ_PROXY — Main Reset Pin Reset Source: mod_por_rst_n (access R/W1TC)
  [0] RST_SRC_MCU_RESET_PIN_PROXY — Rest Caused by MCU Reset Pin Reset Source: mod_por_rst_n (access R/W1TC)
0x1A17C MCU_CTRL_MMR_CFG0_RST_MAGIC_WORD_PROXY
  [31:0] RST_MAGIC_WORD_MCU_MAGIC_WORD_PROXY — After a MCU_PORz reset this bit field resets to 0x00000000.While this bit field remains 0x00000000 any reset from the Main Domain also propagates through the MCU domain. If the application does not require reset isolation of the MCU domain, it shall leave this bit field with a value of 0x00000000.If the application does require reset isolation of the MCU domain afterthe initial boot, then the MCU R5FSS CPU must write a nonzero value to themagic word. The actual value is left to software and different values maybe used to convey information, but in order to isolate the MCU domainfrom any warm reset sources that triggers main_resetz, the value must be non-zero.If the value is nonzero and a Main domain warm reset that triggers main_resetz occurs in the main domain, the MCU R5FSS will not be reset. The Main domain bootloader must read this value to determine that the MCU R5FSS is already initialized, and has configured reset isolation. The Main domain bootloader then also skips any initialization steps involving bootstrapping the R5FSS (as it is is already running).Note that MCU_PORz reset is never blocked by a nonzero magic word. Reset Source: mcu_chip1_rst_n
0x1A180 MCU_CTRL_MMR_CFG0_ISO_CTRL_PROXY
  [1] ISO_CTRL_MCU_DBG_ISO_EN_PROXY — Isolates the MCU domain from Debug Field values (others are reserved):undefined - undefinedundefined - undefined1'b0 - R5FSS is not debug isolated1'b1 - R5FSS is isolated from debug if RST_MAGIC_WORD is also nonzero Reset Source: mcu_chip1_rst_n
  [0] ISO_CTRL_MCU_RST_ISO_EN_PROXY — Isolates the MCU domain from Warm Reset initiated by MainField values (others are reserved):undefined - undefinedundefined - undefined1'b0 - R5FSS is not reset isolated1'b1 - R5FSS is isolated from main warm reset if RST_MAGIC_WORD is also nonzero Reset Source: mcu_chip1_rst_n
0x1A190 MCU_CTRL_MMR_CFG0_VDD_CORE_GLDTC_CTRL_PROXY
  [31] VDD_CORE_GLDTC_CTRL_PWDB_PROXY — Power down - active low. 0 - Deactivate all functions 1 - Activate glitch detectors Reset Source: mcu_chip1_rst_n
  [30] VDD_CORE_GLDTC_CTRL_RSTB_PROXY — Reset - active low. To ensure proper operation, rstb must be not be de-asserted for at least 100 ns after power-up (pwdb de-asserted). Additionally, rstb must be toggled low at least 200 ns after any change in threshold or low-pass filter settings to prevent abnormal trigger events. 0 - Reset glitch detector flags 1 - Glitch detection flags are activated Reset Source: mcu_chip1_rst_n
  [18:16] VDD_CORE_GLDTC_CTRL_LP_FILTER_SEL_PROXY — Selects the glitch detect low-pass filter bandwidthField values (others are reserved):3'b000 - 150 kHz3'b001 - 125 kHz3'b010 - 100 kHz3'b011 - 80 kHz3'b100 - 60 kHz3'b101 - 45 kHz3'b110 - 30 kHz3'b111 - 15 kHz Reset Source: mcu_chip1_rst_n
  [13:8] VDD_CORE_GLDTC_CTRL_THRESH_HI_SEL_PROXY — Selects the high voltage glitch threshold as a percentage of the monitored voltageField values (others are reserved):6'b000000 - 93.5% of VDD6'b000001 - 94.0% of VDD6'b000010 - 94.5% of VDD6'b000011 - 95.0% of VDD6'b000100 - 95.5% of VDD6'b000101 - 96.0% of VDD6'b000110 - 96.5% of VDD6'b000111 - 97.0% of VDD6'b001000 - 97.5% of VDD6'b001001 - 98.0% of VDD6'b001010 - 98.5% of VDD6'b001011 - 99.0% of VDD6'b001100 - 99.5% of VDD6'b001101 - 100.0% of VDD6'b001110 - 100.5% of VDD6'b001111 - 101.0% of VDD6'b010000 - 101.5% of VDD6'b010001 - 102.0% of VDD6'b010010 - 102.5% of VDD6'b010011 - 103.0% of VDD6'b010100 - 103.5% of VDD6'b010101 - 104.0% of VDD6'b010110 - 104.5% of VDD6'b010111 - 105.0% of VDD6'b011000 - 105.5% of VDD6'b011001 - 106.0% of VDD6'b011010 - 106.5% of VDD6'b011011 - 107.0% of VDD6'b011100 - 107.5% of VDD6'b011101 - 108.0% of VDD6'b011110 - 108.5% of VDD6'b011111 - 109.0% of VDD6'b100000 - 109.5% of VDD6'b100001 - 110.0% of VDD6'b100010 - 111.0% of VDD6'b100011 - 112.0% of VDD6'b100100 - 113.0% of VDD6'b100101 - 114.0% of VDD6'b100110 - 115.0% of VDD6'b100111 - 116.0% of VDD6'b101000 - 117.0% of VDD6'b101001 - 118.0% of VDD6'b101010 - 119.0% of VDD6'b101011 - 120.0% of VDD6'b101100 - 121.0% of VDD6'b101101 - 122.0% of VDD6'b101110 - 123.0% of VDD6'b101111 - 124.0% of VDD6'b110000 - 125.0% of VDD6'b110001 - 126.0% of VDD6'b110010 - 127.0% of VDD6'b110011 - 128.0% of VDD6'b110100 - 129.0% of VDD6'b110101 - 130.0% of VDD6'b110110 - 131.0% of VDD6'b110111 - 132.0% of VDD6'b111000 - 133.0% of VDD6'b111001 - 134.0% of VDD6'b111010 - 135.0% of VDD6'b111011 - 136.0% of VDD6'b111100 - 137.0% of VDD6'b111101 - 138.0% of VDD6'b111110 - 139.0% of VDD6'b111111 - 140.0% of VDD Reset Source: mcu_chip1_rst_n
  [5:0] VDD_CORE_GLDTC_CTRL_THRESH_LO_SEL_PROXY — Selects the low voltage glitch threshold as a percentage of the monitored voltageField values (others are reserved):6'b000000 - 106.5% of VDD6'b000001 - 106.0% of VDD6'b000010 - 105.5% of VDD6'b000011 - 105.0% of VDD6'b000100 - 104.5% of VDD6'b000101 - 104.0% of VDD6'b000110 - 103.5% of VDD6'b000111 - 103.0% of VDD6'b001000 - 102.5% of VDD6'b001001 - 102.0% of VDD6'b001010 - 101.5% of VDD6'b001011 - 101.0% of VDD6'b001100 - 100.5% of VDD6'b001101 - 100.0% of VDD6'b001110 - 99.5% of VDD6'b001111 - 99.0% of VDD6'b010000 - 98.5% of VDD6'b010001 - 98.0% of VDD6'b010010 - 97.5% of VDD6'b010011 - 97.0% of VDD6'b010100 - 96.5% of VDD6'b010101 - 96.0% of VDD6'b010110 - 95.5% of VDD6'b010111 - 95.0% of VDD6'b011000 - 94.5% of VDD6'b011001 - 94.0% of VDD6'b011010 - 93.5% of VDD6'b011011 - 93.0% of VDD6'b011100 - 92.5% of VDD6'b011101 - 92.0% of VDD6'b011110 - 91.5% of VDD6'b011111 - 91.0% of VDD6'b100000 - 90.5% of VDD6'b100001 - 90.0% of VDD6'b100010 - 89.0% of VDD6'b100011 - 88.0% of VDD6'b100100 - 87.0% of VDD6'b100101 - 86.0% of VDD6'b100110 - 85.0% of VDD6'b100111 - 84.0% of VDD6'b101000 - 83.0% of VDD6'b101001 - 82.0% of VDD6'b101010 - 81.0% of VDD6'b101011 - 80.0% of VDD6'b101100 - 79.0% of VDD6'b101101 - 78.0% of VDD6'b101110 - 77.0% of VDD6'b101111 - 76.0% of VDD6'b110000 - 75.0% of VDD6'b110001 - 74.0% of VDD6'b110010 - 73.0% of VDD6'b110011 - 72.0% of VDD6'b110100 - 71.0% of VDD6'b110101 - 70.0% of VDD6'b110110 - 69.0% of VDD6'b110111 - 68.0% of VDD6'b111000 - 67.0% of VDD6'b111001 - 66.0% of VDD6'b111010 - 65.0% of VDD6'b111011 - 64.0% of VDD6'b111100 - 63.0% of VDD6'b111101 - 62.0% of VDD6'b111110 - 61.0% of VDD6'b111111 - 60.0% of VDD Reset Source: mcu_chip1_rst_n
0x1A1B0 MCU_CTRL_MMR_CFG0_VDD_CORE_GLDTC_STAT_PROXY ro
  [8] VDD_CORE_GLDTC_STAT_THRESH_HI_FLAG_PROXY — High voltage flag. This flag is cleared by clearing the VDD_CORE_GLDTC_CTRL_rstb bit. 0 - No high voltage detected 1 - Voltage above the high voltage threshold was detected. Reset Source: mcu_chip1_rst_n
  [0] VDD_CORE_GLDTC_STAT_THRESH_LOW_FLAG_PROXY — Low voltage flag. This flag is cleared by clearing the VDD_CORE_GLDTC_CTRL_rstb bit. 0 - No low voltage detected 1 - Voltage below the low voltage threshold was detected. Reset Source: mcu_chip1_rst_n
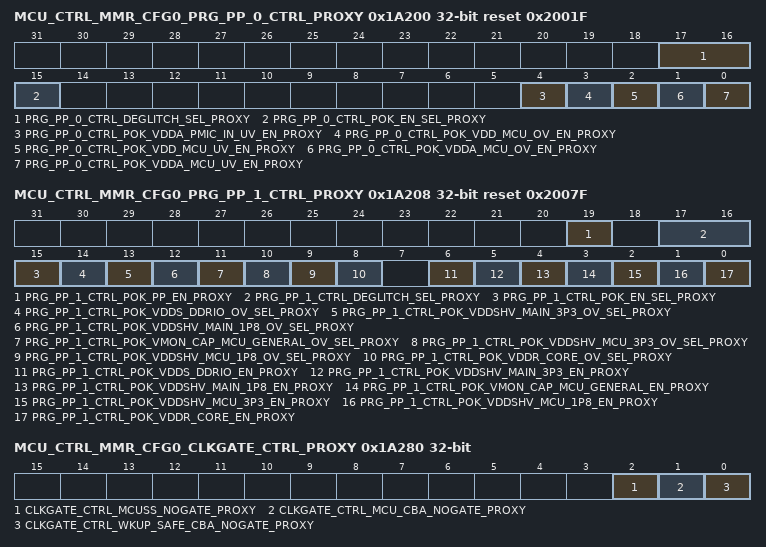
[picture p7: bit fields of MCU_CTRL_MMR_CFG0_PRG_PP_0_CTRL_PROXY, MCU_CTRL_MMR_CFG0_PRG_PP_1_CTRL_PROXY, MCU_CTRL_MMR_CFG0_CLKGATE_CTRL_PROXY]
0x1A200 MCU_CTRL_MMR_CFG0_PRG_PP_0_CTRL_PROXY reset 0x2001F
  [17:16] PRG_PP_0_CTRL_DEGLITCH_SEL_PROXY — Deglitch period for PRG_PP0 POKs:2'b00 - 5 us2'b01 -10 us2'b10 - 15 us2'b11 - 20us Reset Source: mod_por_rst_n
  [15] PRG_PP_0_CTRL_POK_EN_SEL_PROXY — Select POK activate source0 - POK activates come from hardware tie-offs1 - POK activates come from PRG_PP0_CTRL register Reset Source: mod_por_rst_n
  [4] PRG_PP_0_CTRL_POK_VDDA_PMIC_IN_UV_EN_PROXY — Activate VDDA_PMIC_IN undervoltage POK detection0 - POK detection deactivated1 - POK detection activated Reset Source: mod_por_rst_n
  [3] PRG_PP_0_CTRL_POK_VDD_MCU_OV_EN_PROXY — Activate VDD_MCU overvoltage POK detection0 - POK detection deactivated1 - POK detection activated Reset Source: mod_por_rst_n
  [2] PRG_PP_0_CTRL_POK_VDD_MCU_UV_EN_PROXY — Activate VDD_MCU undervoltage POK detection0 - POK detection deactivated1 - POK detection activated Reset Source: mod_por_rst_n
  [1] PRG_PP_0_CTRL_POK_VDDA_MCU_OV_EN_PROXY — Activate 1.8V VDDA_MCU overvoltage POK detection0 - POK detection deactivated1 - POK detection activated Reset Source: mod_por_rst_n
  [0] PRG_PP_0_CTRL_POK_VDDA_MCU_UV_EN_PROXY — Activate 1.8V VDDA_MCU undervoltage POK detection0 - POK detection deactivated1 - POK detection activated Reset Source: mod_por_rst_n
0x1A208 MCU_CTRL_MMR_CFG0_PRG_PP_1_CTRL_PROXY reset 0x2007F
  [19] PRG_PP_1_CTRL_POK_PP_EN_PROXY — POK ping-pong activate. When set, activatesautomatic switching between undervoltage andovervoltage detection on PRG_PP1 (POK_VDDR_CORE, POK_VDDSHV_MCU_1P8, POK_VDDSHV_MCU_3P3, POK_VMON_CAP_MCU_GENERAL, POK_VDDSHV_MAIN_1P8, POK_VDDSHV_MAIN_3P3, and POK_VDDS_DDRIO) POKs. This bit has no effect if the POK's ov_sel bit = 1.0 - No pingpong operation. UV/OV operationselected by each POK ov_sel bit1 - Pingpong operation activated . Reset Source: mod_por_rst_n
  [17:16] PRG_PP_1_CTRL_DEGLITCH_SEL_PROXY — Deglitch period for PRG_PP1 POKs:2'b00 - 5 us2'b01 -10 us2'b10 - 15 us2'b11 - 20us Reset Source: mod_por_rst_n
  [15] PRG_PP_1_CTRL_POK_EN_SEL_PROXY — Select POK activate source0 - POK activates come from hardware tie-offs1 - POK activates come from PRG_PP1_CTRL register Reset Source: mod_por_rst_n
  [14] PRG_PP_1_CTRL_POK_VDDS_DDRIO_OV_SEL_PROXY — POK_VDDS_DDRIO mode: 0 = Undervoltage (pok_pp_en = 0) Ping-Pong (pok_pp_en = 1) 1 = Overvoltage (pok_pp_en = x) Reset Source: mod_por_rst_n
  [13] PRG_PP_1_CTRL_POK_VDDSHV_MAIN_3P3_OV_SEL_PROXY — POK_VDDSHV_MAIN_3P3 mode: 0 = Undervoltage (pok_pp_en = 0) Ping-Pong (pok_pp_en = 1) 1 = Overvoltage (pok_pp_en = x) Reset Source: mod_por_rst_n
  [12] PRG_PP_1_CTRL_POK_VDDSHV_MAIN_1P8_OV_SEL_PROXY — POK_VDDSHV_MAIN_1P8 mode: 0 = Undervoltage (pok_pp_en = 0) Ping-Pong (pok_pp_en = 1) 1 = Overvoltage (pok_pp_en = x) Reset Source: mod_por_rst_n
  [11] PRG_PP_1_CTRL_POK_VMON_CAP_MCU_GENERAL_OV_SEL_PROXY — POK_VMON_CAP_MCU_GENERAL mode: 0 = Undervoltage (pok_pp_en = 0) Ping-Pong (pok_pp_en = 1) 1 = Overvoltage (pok_pp_en = x) Reset Source: mod_por_rst_n
  [10] PRG_PP_1_CTRL_POK_VDDSHV_MCU_3P3_OV_SEL_PROXY — POK_VDDSHV_MCU_3P3 mode: 0 = Undervoltage (pok_pp_en = 0) Ping-Pong (pok_pp_en = 1) 1 = Overvoltage (pok_pp_en = x) Reset Source: mod_por_rst_n
  [9] PRG_PP_1_CTRL_POK_VDDSHV_MCU_1P8_OV_SEL_PROXY — POK_VDDSHV_MCU_1P8 mode: 0 = Undervoltage (pok_pp_en = 0) Ping-Pong (pok_pp_en = 1) 1 = Overvoltage (pok_pp_en = x) Reset Source: mod_por_rst_n
  [8] PRG_PP_1_CTRL_POK_VDDR_CORE_OV_SEL_PROXY — POK_VDDR_CORE Mode: 0 = Undervoltage (pok_pp_en = 0) Ping-Pong (pok_pp_en = 1) 1 = Overvoltage (pok_pp_en = x) Reset Source: mod_por_rst_n
  [6] PRG_PP_1_CTRL_POK_VDDS_DDRIO_EN_PROXY — Activate POK_VDDS_DDRIO (if pok_en_sel = 1): 0 = POK Detection Deactivated 1 = POK Detection Activated Reset Source: mod_por_rst_n
  [5] PRG_PP_1_CTRL_POK_VDDSHV_MAIN_3P3_EN_PROXY — Activate POK_VDDSHV_MAIN_3P3 (if pok_en_sel = 1): 0 = POK Detection Deactivated 1 = POK Detection Activated Reset Source: mod_por_rst_n
  [4] PRG_PP_1_CTRL_POK_VDDSHV_MAIN_1P8_EN_PROXY — Activate POK_VDDSHV_MAIN_1P8 (if pok_en_sel = 1): 0 = POK Detection Deactivated 1 = POK Detection Activated Reset Source: mod_por_rst_n
  [3] PRG_PP_1_CTRL_POK_VMON_CAP_MCU_GENERAL_EN_PROXY — Activate POK_VMON_CAP_MCU_GENERAL (if pok_en_sel = 1): 0 = POK Detection Deactivated 1 = POK Detection Activated Reset Source: mod_por_rst_n
  [2] PRG_PP_1_CTRL_POK_VDDSHV_MCU_3P3_EN_PROXY — Activate POK_VDDSHV_MCU_3P3 (if pok_en_sel = 1): 0 = POK Detection Deactivated 1 = POK Detection Activated Reset Source: mod_por_rst_n
  [1] PRG_PP_1_CTRL_POK_VDDSHV_MCU_1P8_EN_PROXY — Activate POK_VDDSHV_MCU_1P8 (if pok_en_sel = 1): 0 = POK Detection Deactivated 1 = POK Detection Activated Reset Source: mod_por_rst_n
  [0] PRG_PP_1_CTRL_POK_VDDR_CORE_EN_PROXY — Activate POK_VDDR_CORE (if pok_en_sel = 1): 0 = POK Detection Deactivated 1 = POK Detection Activated Reset Source: mod_por_rst_n
0x1A280 MCU_CTRL_MMR_CFG0_CLKGATE_CTRL_PROXY
  [2] CLKGATE_CTRL_MCUSS_NOGATE_PROXY — MCU Subsystem clock gate deactivate. 0 - Clocks are gated on idle for power savings 1 - Clocks are not gated on idle, power saving deactivated Reset Source: mod_por_rst_n
  [1] CLKGATE_CTRL_MCU_CBA_NOGATE_PROXY — MCU domain Data bus (mcu_cbass) clock gate deactivate. 0 - Clocks are gated on idle for power savings 1 - Clocks are not gated on idle, power saving deactivated Reset Source: mod_por_rst_n
  [0] CLKGATE_CTRL_WKUP_SAFE_CBA_NOGATE_PROXY — WKUP domain Infrastructure bus (wkup_safe_cbass) clock gate deactivate. 0 - Clocks are gated on idle for power savings 1 - Clocks are not gated on idle, power saving deactivated Reset Source: mod_por_rst_n
0x1B008 MCU_CTRL_MMR_CFG0_LOCK6_KICK0_PROXY
  [31:0] LOCK6_KICK0_PROXY — - KICK0 component Reset Source: mod_g_rst_n
0x1B00C MCU_CTRL_MMR_CFG0_LOCK6_KICK1_PROXY
  [31:0] LOCK6_KICK1_PROXY — - KICK1 component Reset Source: mod_g_rst_n
{0x1B100+4i} MCU_CTRL_MMR_CFG0_CLAIMREG_P6_R{i} (i=0..5)
  [31:0] CLAIMREG_P6_R{i} — Claim bits for Partition 6 Reset Source: mod_g_rst_n
